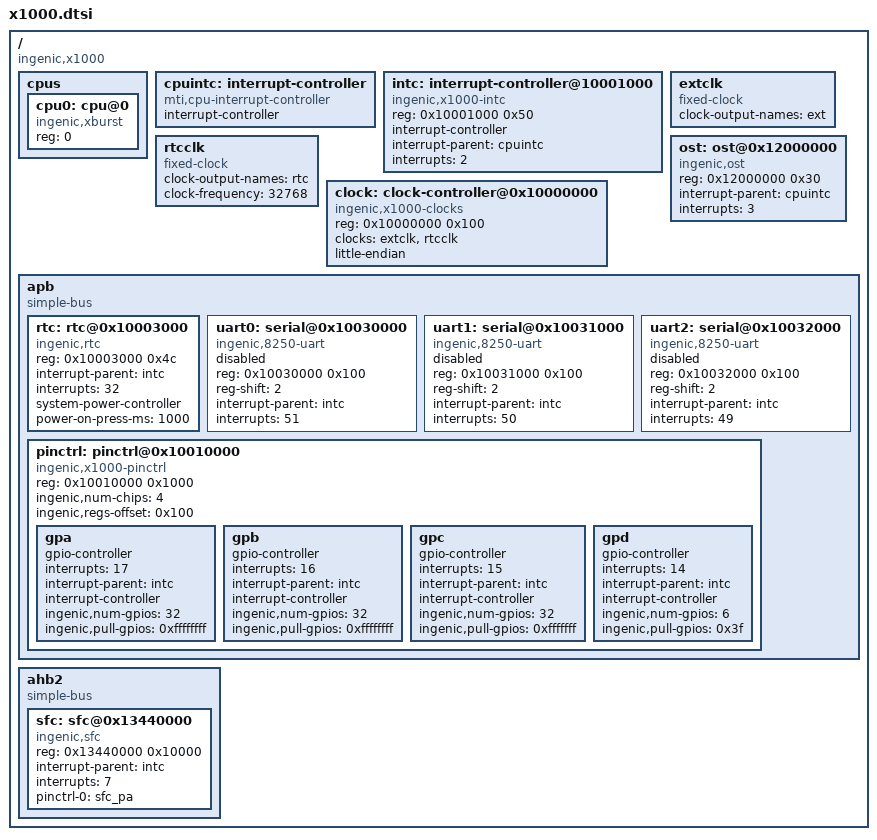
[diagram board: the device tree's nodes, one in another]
// SPDX-License-Identifier: GPL-2.0

/ {
	#address-cells = <1>;
	#size-cells = <1>;
	compatible = "ingenic,x1000", "ingenic,x1000e";

	cpus {
		#address-cells = <1>;
		#size-cells = <0>;

		cpu0: cpu@0 {
			compatible = "ingenic,xburst";
			device_type = "cpu";
			reg = <0>;
		};
	};

	cpuintc: interrupt-controller {
		#address-cells = <0>;
		#interrupt-cells = <1>;
		interrupt-controller;
		compatible = "mti,cpu-interrupt-controller";
	};

	intc: interrupt-controller@10001000 {
		compatible = "ingenic,x1000-intc","ingenic,jz4780-intc";
		reg = <0x10001000 0x50>;

		interrupt-controller;
		#interrupt-cells = <1>;

		interrupt-parent = <&cpuintc>;
		interrupts = <2>;
	};

	extclk: extclk {
		compatible = "fixed-clock";
		clock-output-names ="ext";
		#clock-cells = <0>;
	};

	rtcclk: rtcclk {
		compatible = "fixed-clock";
		clock-output-names ="rtc";
		#clock-cells = <0>;
		clock-frequency = <32768>;
	};

	clock: clock-controller@0x10000000 {
		compatible = "ingenic,x1000-clocks", "syscon";
		reg = <0x10000000 0x100>;
		clocks = <&extclk>, <&rtcclk>;
		clock-names = "ext", "rtc";
		#clock-cells = <1>;
		little-endian;
	};

	ost: ost@0x12000000 {
		compatible = "ingenic,ost";
		reg = <0x12000000 0x30>;
		interrupt-parent = <&cpuintc>;
		interrupt-names = "sys_ost";
		interrupts = <3>;
	};

	apb {
		compatible = "simple-bus";
		#address-cells = <1>;
		#size-cells = <1>;
		ranges = <>;

		rtc: rtc@0x10003000 {
			compatible = "ingenic,rtc";
			reg = <0x10003000 0x4c>;
			interrupt-parent = <&intc>;
			interrupts = <32>;
			system-power-controller;
			power-on-press-ms = <1000>;
		};

		uart0: serial@0x10030000 {
			compatible = "ingenic,8250-uart";
			reg = <0x10030000 0x100>;
			reg-shift = <2>;
			interrupt-parent = <&intc>;
			interrupts = <51>;
			status = "disabled";
		};

		uart1: serial@0x10031000 {
			compatible = "ingenic,8250-uart";
			reg = <0x10031000 0x100>;
			reg-shift = <2>;
			interrupt-parent = <&intc>;
			interrupts = <50>;
			status = "disabled";
		};

		uart2: serial@0x10032000 {
			compatible = "ingenic,8250-uart";
			reg = <0x10032000 0x100>;
			reg-shift = <2>;
			interrupt-parent = <&intc>;
			interrupts = <49>;
			status = "disabled";
		};

		pinctrl: pinctrl@0x10010000 {
			compatible = "ingenic,x1000-pinctrl";
			reg = <0x10010000 0x1000>;
			ingenic,num-chips = <4>;
			ingenic,regs-offset = <0x100>;
			gpa: gpa {
				gpio-controller;
				#gpio-cells = <3>;
				#ingenic,pincfg-cells = <3>;
				#ingenic,pinmux-cells = <2>;
				interrupts = <17>;
				interrupt-parent = <&intc>;
				interrupt-controller;
				#interrupt-cells = <3>;
				ingenic,num-gpios = <32>;
				ingenic,pull-gpios = <0xffffffff>;
			};

			gpb: gpb {
				gpio-controller;
				#gpio-cells = <3>;
				#ingenic,pincfg-cells = <3>;
				#ingenic,pinmux-cells = <2>;
				interrupts = <16>;
				interrupt-parent = <&intc>;
				interrupt-controller;
				#interrupt-cells = <3>;
				ingenic,num-gpios = <32>;
				ingenic,pull-gpios = <0xffffffff>;
			};

			gpc: gpc {
				gpio-controller;
				#gpio-cells = <3>;
				#ingenic,pincfg-cells = <3>;
				#ingenic,pinmux-cells = <2>;
				interrupts = <15>;
				interrupt-parent = <&intc>;
				interrupt-controller;
				#interrupt-cells = <3>;
				ingenic,num-gpios = <32>;
				ingenic,pull-gpios = <0xfffffff>;
			};

			gpd: gpd {
				gpio-controller;
				#gpio-cells = <3>;
				#ingenic,pincfg-cells = <3>;
				#ingenic,pinmux-cells = <2>;
				interrupts = <14>;
				interrupt-parent = <&intc>;
				interrupt-controller;
				#interrupt-cells = <3>;
				ingenic,num-gpios = <6>;
				ingenic,pull-gpios = <0x3f>;
			};
		};
	};

	ahb2 {
		compatible = "simple-bus";
		#address-cells = <1>;
		#size-cells = <1>;
		ranges = <>;

		sfc: sfc@0x13440000 {
			compatible = "ingenic,sfc";
			reg = <0x13440000 0x10000>;
			interrupt-parent = <&intc>;
			interrupts = <7>;
			pinctrl-names = "default";
			pinctrl-0 = <&sfc_pa>;
		};
	};
};

#include "x1000-pinctrl.dtsi"
